# USB0_VBP2AHB_WRAP_CONTROLLER_VBP_USB3_CORE_CAP register map
Vendor: Texas Instruments
Peripheral module from a debugger description file (folder J722S).
Registers are 32-bit, read-only, reset 0x1100020 unless marked. A register's access mark holds for its fields unless they carry their own. Offsets are as the file gives them; lines under a group give offsets from that group; [hi:lo] are bit positions; {n}, {i} and the like mark numbered series; 'fields as' and 'values as' point back to an identical list; <NAME> marks a mode.

## USB0_VBP2AHB_WRAP_CONTROLLER_VBP_USB3_CORE_CAP
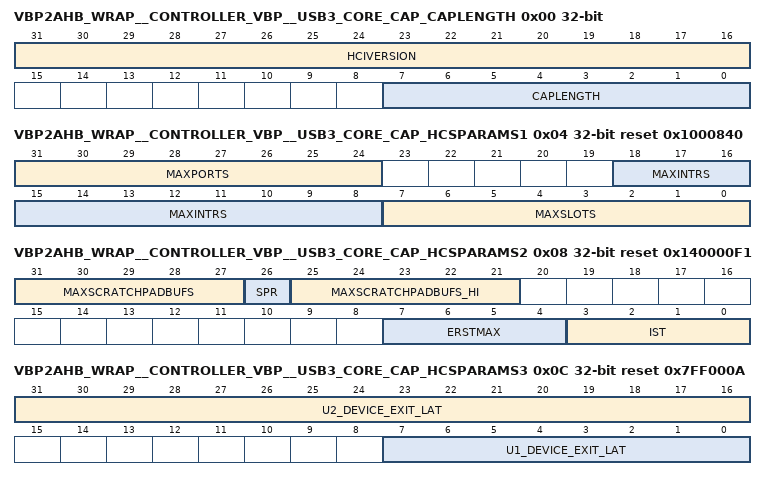
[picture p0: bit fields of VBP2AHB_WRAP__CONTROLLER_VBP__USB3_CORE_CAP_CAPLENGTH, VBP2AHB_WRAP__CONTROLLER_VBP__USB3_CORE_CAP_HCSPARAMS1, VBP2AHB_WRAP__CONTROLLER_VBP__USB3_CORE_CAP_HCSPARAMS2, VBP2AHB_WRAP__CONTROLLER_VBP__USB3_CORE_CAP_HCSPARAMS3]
0x00 VBP2AHB_WRAP__CONTROLLER_VBP__USB3_CORE_CAP_CAPLENGTH — Capability Registers Length Host Controller Operational Registers = Base address + CAPLENGTH where CAPLENGTH is DWC_USB3_HOST_CAP_REG_LEN whose default value is 20h.
  [31:16] HCIVERSION — HC Interface Version Number [HCIVERSION]
  [7:0] CAPLENGTH — Capability Registers Length [CAPLENGTH]
0x04 VBP2AHB_WRAP__CONTROLLER_VBP__USB3_CORE_CAP_HCSPARAMS1 reset 0x1000840 — Structural Parameters 1 Register For register definitions, refer to the xHCI specification.
  [31:24] MAXPORTS — Number of Ports [MaxPorts] - Number of ports implemented is defined by the parameter [DWC_USB3_HOST_NUM_U2_ROOT_PORTS + DWC_USB3_HOST_NUM_U3_ROOT_PORTS] - Number of ports enabled is controlled by the controller input signals host_num_u2_port[3:0]+host_num_u3_port[3:0] Note: In USB 2.0-only mode, the host_num_u3_port signal is zero.
  [18:8] MAXINTRS — Number of Interrupters [MaxIntrs] Defined by the configurable parameter DWC_USB3_HOST_NUM_INTERRUPTER_SUPT
  [7:0] MAXSLOTS — Number of device slots [MaxSlots] Defined by configurable parameter DWC_USB3_NUM_DEVICE_SUPT
0x08 VBP2AHB_WRAP__CONTROLLER_VBP__USB3_CORE_CAP_HCSPARAMS2 reset 0x140000F1 — Structural Parameters 2 Register For register definitions, refer to the xHCI specification.
  [31:27] MAXSCRATCHPADBUFS — Max Scratchpad Bufs Lo The value is calculated based on chosen configuration parameter values. Possible values are 1-4.
  [26] SPR — Scratchpad Restore [SPR]
  [25:21] MAXSCRATCHPADBUFS_HI — Max Scratchpad Bufs HI The controller automatically updates this field.
  [7:4] ERSTMAX — Event Ring Segment Table Max [ERST Max]
  [3:0] IST — Isochronous Scheduling Threshold [IST]
0x0C VBP2AHB_WRAP__CONTROLLER_VBP__USB3_CORE_CAP_HCSPARAMS3 reset 0x7FF000A — Structural Parameters 3 Register For register definitions, refer to the xHCI specification.
  [31:16] U2_DEVICE_EXIT_LAT — U2 Device Exit Latency
  [7:0] U1_DEVICE_EXIT_LAT — U1 Device Exit Latency
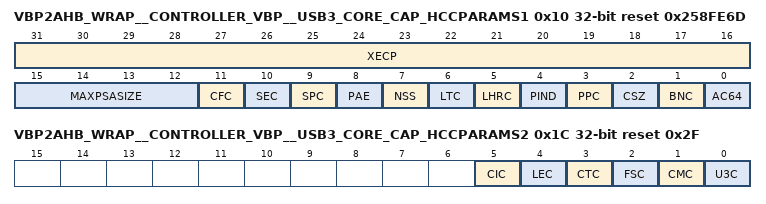
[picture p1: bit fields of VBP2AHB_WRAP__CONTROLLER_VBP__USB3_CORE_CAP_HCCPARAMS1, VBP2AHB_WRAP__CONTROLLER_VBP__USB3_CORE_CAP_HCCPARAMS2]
0x10 VBP2AHB_WRAP__CONTROLLER_VBP__USB3_CORE_CAP_HCCPARAMS1 reset 0x258FE6D — Capability Parameters 1 Register For register definitions, refer to the xHCI specification.
  [31:16] XECP — xHCI Extended Capabilities Pointer [xECP] Based on configuration, controller automatically updates it. Refer to &#60;workspace>/src/DWC_usb3_params.v for details on DWC_USB3_HC_XECP.
  [15:12] MAXPSASIZE — Maximum Primary Stream Array Size [MaxPSASize] For a description of this standard USB register field, see the eXtensible Host Controller Interface for Universal Serial Bus [USB] Specification 3.0.
  [11] CFC — Contiguous Frame ID Capability [CFC]
  [10] SEC — Stopped EDLTA Capability [SEC] For a description of this standard USB register field, see the eXtensible Host Controller Interface for Universal Serial Bus [USB] Specification 3.0.
  [9] SPC — Short Packet Capability [SPC] For a description of this standard USB register field, see the eXtensible Host Controller Interface for Universal Serial Bus [USB] Specification 3.0.
  [8] PAE — Parse All Event Data [PAE] For a description of this standard USB register field, see the eXtensible Host Controller Interface for Universal Serial Bus [USB] Specification 3.0.
  [7] NSS — No Secondary SID Support [NSS] For a description of this standard USB register field, see the eXtensible Host Controller Interface for Universal Serial Bus [USB] Specification 3.0.
  [6] LTC — Latency Tolerance Messaging Capability [LTC] For a description of this standard USB register field, see the eXtensible Host Controller Interface for Universal Serial Bus [USB] Specification 3.0.
  [5] LHRC — Light HC Reset Capability For a description of this standard USB register field, see the eXtensible Host Controller Interface for Universal Serial Bus [USB] Specification 3.0.
  [4] PIND — Port Indicators [PIND] For a description of this standard USB register field, see the eXtensible Host Controller Interface for Universal Serial Bus [USB] Specification 3.0.
  [3] PPC — Port Power Control For a description of this standard USB register field, see the eXtensible Host Controller Interface for Universal Serial Bus [USB] Specification 3.0.
  [2] CSZ — Context Size [CSZ] For a description of this standard USB register field, see the eXtensible Host Controller Interface for Universal Serial Bus [USB] Specification 3.0.
  [1] BNC — BW Negotiation Capability [BNC] For a description of this standard USB register field, see the eXtensible Host Controller Interface for Universal Serial Bus [USB] Specification 3.0.
  [0] AC64 — 64-bit Addressing Capability [AC64] For a description of this standard USB register field, see the eXtensible Host Controller Interface for Universal Serial Bus [USB] Specification 3.0.
0x14 VBP2AHB_WRAP__CONTROLLER_VBP__USB3_CORE_CAP_DBOFF reset 0x560 — Doorbell Offset Register For register definitions, refer to the xHCI specification.
  [31:2] DOORBELL_ARRAY_OFFSET — Doorbell Array Offset - RO Based on configuration, the controller automatically updates it. For a description of this standard USB register field, see the eXtensible Host Controller Interface for Universal Serial Bus [USB] Specification 3.0.
0x18 VBP2AHB_WRAP__CONTROLLER_VBP__USB3_CORE_CAP_RTSOFF reset 0x440 — Runtime Register Space Offset Register
  [31:5] RUNTIME_REG_SPACE_OFFSET — Runtime Register Space Offset Based on configuration, the controller automatically updates it. For a description of this standard USB register field, see the eXtensible Host Controller Interface for Universal Serial Bus [USB] Specification 3.0.
0x1C VBP2AHB_WRAP__CONTROLLER_VBP__USB3_CORE_CAP_HCCPARAMS2 reset 0x2F — Host Controller Capability Parameters 2 For register definitions, refer to the xHCI specification.
  [5] CIC — Configuration Information Capability [CIC] For a description of this standard USB register field, see the eXtensible Host Controller I nterface for Universal Serial Bus [USB] Specification 3.0.
  [4] LEC — Large ESIT Payload Capability [LEC] For a description of this standard USB register field, see the eXtensible Host Controller I nterface for Universal Serial Bus [USB] Specification 3.0.
  [3] CTC — Compliance Transition Capability [CTC] For a description of this standard USB register field, see the eXtensible Host Controller I nterface for Universal Serial Bus [USB] Specification 3.0.
  [2] FSC — Force Save Context Capability [FSC] For a description of this standard USB register field, see the eXtensible Host Controller I nterface for Universal Serial Bus [USB] Specification 3.0.
  [1] CMC — Configure Endpoint Command Max Exit Latency Too Large Capability [CMC] For a description of this standard USB register field, see the eXtensible Host Controller I nterface for Universal Serial Bus [USB] Specification 3.0.
  [0] U3C — U3 Entry Capability [U3C] For a description of this standard USB register field, see the eXtensible Host Controller I nterface for Universal Serial Bus [USB] Specification 3.0.
